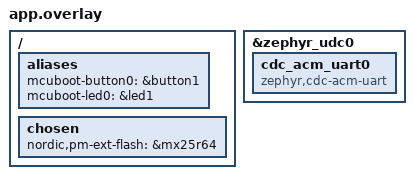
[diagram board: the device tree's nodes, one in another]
/* Configure button and LED for Serial Recovery */
/ {
  aliases {
		mcuboot-button0 = &button1;
		mcuboot-led0 = &led1;
  };
};

/* Step 8.1 - Add external flash */
/ {
	chosen {
		nordic,pm-ext-flash = &mx25r64;
	};
};

&zephyr_udc0 {
	cdc_acm_uart0: cdc_acm_uart0 {
		compatible = "zephyr,cdc-acm-uart";
	};
};
